# StarFive VisionFive 2 v1.3b register map
File version: 0.1
Registers are 32-bit, read-write, no defined reset value unless marked. A register's access mark holds for its fields unless they carry their own. Offsets are from the block's base; [hi:lo] are bit positions; {n}, {i} and the like mark numbered series; 'fields as' and 'values as' point back to an identical list.

## sifive_clint0_0 — From sifive,clint0, peripheral generator
Base 0x02000000
{0x0+4i} msip_{i} (i=0..4) — MSIP Register for hart {i}
{0x4000+8i} mtimecmp_{i} 64-bit (i=0..4) — MTIMECMP Register for hart {i}
0xBFF8 mtime 64-bit

## sifive_plic0_0 — From sifive,plic0, peripheral generator
Base 0x0C000000
{0x0+4i} priority_{i} (i=1..136) — PRIORITY Register for interrupt id {i}
{0x1000+4i} pending_{i} (i=0..3) — PENDING Register for interrupt ids {32i+31} to {32i}
0x1010 pending_4 — PENDING Register for interrupt ids 136 to 128
{0x2000+0x80*i} enable_0_{i} (i=0..4) — ENABLE Register for interrupt ids 31 to 0 for hart {i}
{0x2004+0x80*i} enable_1_{i} (i=0..4) — ENABLE Register for interrupt ids 63 to 32 for hart {i}
{0x2008+0x80*i} enable_2_{i} (i=0..4) — ENABLE Register for interrupt ids 95 to 64 for hart {i}
{0x200C+0x80*i} enable_3_{i} (i=0..4) — ENABLE Register for interrupt ids 127 to 96 for hart {i}
{0x2010+0x80*i} enable_4_{i} (i=0..4) — ENABLE Register for interrupt ids 136 to 128 for hart {i}
{0x200000+0x1000*i} threshold_{i} (i=0..4) — PRIORITY THRESHOLD Register for hart {i}
{0x200004+0x1000*i} claimplete_{i} (i=0..4) — CLAIM and COMPLETE Register for hart {i}

## starfive_jh7110_pwm_0 — From starfive,jh7110-pwm, peripheral generator
Base 0x120D0000
0x00 cntr — PTC counter register
  [31:0] cntr — PWM PTC counter
0x04 hrc — PTC duty-cycle register
  [31:0] hrc — PWM PTC duty-cycle value
0x08 lrc — PTC period register
  [31:0] lrc — PWM PTC period value
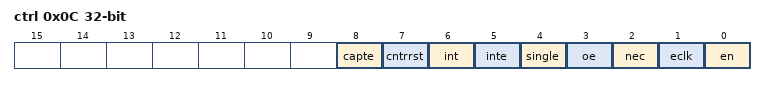
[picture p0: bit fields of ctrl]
0x0C ctrl — PTC control register
  [8] capte — PWM PTC capte
  [7] cntrrst — PWM PTC counter reset
  [6] int — PWM PTC interrupt
  [5] inte — PWM PTC interrupt enable
  [4] single — PWM PTC single
  [3] oe — PWM PTC oe
  [2] nec — PWM PTC nec
  [1] eclk — PWM PTC enable clock
  [0] en — PWM PTC enable

## starfive_jh7110_aoncrg_0 — From starfive,jh7110-aoncrg, peripheral generator
Base 0x17000000
0x00 clk_osc — Oscillator Clock
  [23:0] clk_divcfg — Clock divider coefficient: Max=4, Default=4, Min=4, Typical=4
0x04 clk_aon_apb — AON APB Function Clock
  [29:24] clk_mux_sel — Clock multiplexing selector: clk_osc_div4, clk_osc
0x08 clk_ahb_gmac5 — AHB GMAC5 Clock
  [31] clk_icg — 1: Clock enable, 0: Clock disable
0x0C clk_axi_gmac5 — AXI GMAC5 Clock
  [31] clk_icg — 1: Clock enable, 0: Clock disable
0x10 clk_gmac0_rmii_rtx — GMAC0 RMII RTX Clock
  [23:0] clk_divcfg — Clock divider coefficient: Max=30, Default=2, Min=2, Typical=2
0x14 clk_gmac5_axi64_tx — GMAC5 AXI64 Clock Transmitter
  [29:24] clk_mux_sel — Clock multiplexing selector: u0_sys_crg_clk_gmac0_gtxclk, clk_gmac0_rmii_rtx
0x18 clk_gmac5_axi64_txi — GMAC5 AXI64 Clock Transmission Inverter
  [30] clk_polarity — 1: Clock inverter, 0: Clock buffer
0x1C clk_gmac5_axi64_rx — GMAC5 AXI64 Clock Receiver
  [23:0] dly_chain_sel — Selector delay chain stage number, totally 32 stages, -50 ps each stage. The register value indicates the delay chain stage number. For example, diy_chain_sel=1 means to delay 1 stage.
0x20 clk_gmac5_axi64_rxi — GMAC5 AXI64 Clock Receiving Inverter
  [30] clk_polarity — 1: Clock inverter, 0: Clock buffer
0x24 clk_optc_apb — OPTC APB Clock
  [31] clk_icg — 1: Clock enable, 0: Clock disable
0x28 clk_rtc_hms_apb — RTC HMS APB Clock
  [31] clk_icg — 1: Clock enable, 0: Clock disable
0x2C clk_rtc_internal — RTC Internal Clock
  [23:0] clk_divcfg — Clock divider coefficient: Max=1022, Default=750, Min=750, Typical=750
0x30 clk_rtc_hms_osc32k — RTC HMS Clock Oscillator 32K
  [29:24] clk_mux_sel — Clock multiplexing selector: clk_rtc, clk_rtc_internal
0x34 clk_rtc_hms_cal — RTC HMS Clock Calculator
  [31] clk_icg — 1: Clock enable, 0: Clock disable
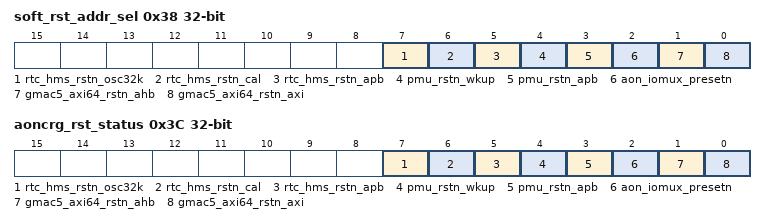
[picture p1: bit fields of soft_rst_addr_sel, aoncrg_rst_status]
0x38 soft_rst_addr_sel — Software RESET Address Selector
  [7] rtc_hms_rstn_osc32k — 1: Assert reset, 0: De-assert reset
  [6] rtc_hms_rstn_cal — 1: Assert reset, 0: De-assert reset
  [5] rtc_hms_rstn_apb — 1: Assert reset, 0: De-assert reset
  [4] pmu_rstn_wkup — 1: Assert reset, 0: De-assert reset
  [3] pmu_rstn_apb — 1: Assert reset, 0: De-assert reset
  [2] aon_iomux_presetn — 1: Assert reset, 0: De-assert reset
  [1] gmac5_axi64_rstn_ahb — 1: Assert reset, 0: De-assert reset
  [0] gmac5_axi64_rstn_axi — 1: Assert reset, 0: De-assert reset
0x3C aoncrg_rst_status — AONCRG RESET Status
  fields as soft_rst_addr_sel

## starfive_jh7110_aon_syscon_0 — From starfive,jh7110-aon-syscon, peripheral generator
Base 0x17010000
0x00 aon_sysconsaif_syscfg0
  [31:0] aon_gp_reg
0x04 aon_sysconsaif_syscfg4
  [3:0] u0_boot_ctrl_boot_status ro
0x08 aon_sysconsaif_syscfg8
  [31:0] u0_boot_ctrl_boot_vector_31_0 ro
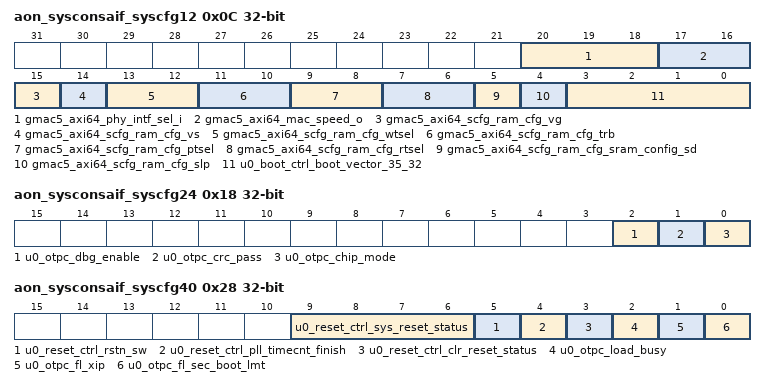
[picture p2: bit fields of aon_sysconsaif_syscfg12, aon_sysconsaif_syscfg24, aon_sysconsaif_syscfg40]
0x0C aon_sysconsaif_syscfg12
  [20:18] gmac5_axi64_phy_intf_sel_i — Active PHY Selected. When you have multiple GMAC PHY interfaces in your configuration, this field indicates the sampled value of the PHY selector during reset de-assertion. Values: 0x0 - GMII or MII, 0x1 - RGMII, 0x2 - SGMII, 0x3 - TBI, 0x4 - RMII, 0x5 - RTBI, 0x6 - SMII, 0x7 - REVMII
  [17:16] gmac5_axi64_mac_speed_o ro
  [15] gmac5_axi64_scfg_ram_cfg_vg — SRAM/ROM configuration. VG: timing setting for debug purpose, default is 1'b1.
  [14] gmac5_axi64_scfg_ram_cfg_vs — SRAM/ROM configuration. VS: timing setting for debug purpose, default is 1'b1.
  [13:12] gmac5_axi64_scfg_ram_cfg_wtsel — SRAM/ROM configuration. WTSEL: timing setting for debug purpose, default is 2'b01.
  [11:10] gmac5_axi64_scfg_ram_cfg_trb — SRAM/ROM configuration. TRB: timing setting for debug purpose, default is 2'b01.
  [9:8] gmac5_axi64_scfg_ram_cfg_ptsel — SRAM/ROM configuration. PTSEL: timing setting for debug purpose, default is 2'b01.
  [7:6] gmac5_axi64_scfg_ram_cfg_rtsel — SRAM/ROM configuration. RTSEL: timing setting for debug purpose, default is 2'b01.
  [5] gmac5_axi64_scfg_ram_cfg_sram_config_sd — SRAM/ROM configuration. SD: shutdown enable, high active, default is low.
  [4] gmac5_axi64_scfg_ram_cfg_slp — SRAM/ROM configuration. SLP: sleep enable, high active, default is low.
  [3:0] u0_boot_ctrl_boot_vector_35_32 ro
0x10 aon_sysconsaif_syscfg16
  [31:0] gmac5_axi64_ptp_timestamp_o_31_0 ro
0x14 aon_sysconsaif_syscfg20
  [31:0] gmac5_axi64_ptp_timestamp_o_63_32 ro
0x18 aon_sysconsaif_syscfg24
  [2] u0_otpc_dbg_enable ro, [1] u0_otpc_crc_pass ro, [0] u0_otpc_chip_mode ro
0x1C aon_sysconsaif_syscfg28
  [31:0] u0_otpc_fl_func_lock ro
0x20 aon_sysconsaif_syscfg32
  [31:0] u0_otpc_fl_pll0_lock ro
0x24 aon_sysconsaif_syscfg36
  [31:0] u0_otpc_fl_pll1_lock ro
0x28 aon_sysconsaif_syscfg40
  [9:6] u0_reset_ctrl_sys_reset_status ro, [5] u0_reset_ctrl_rstn_sw, [4] u0_reset_ctrl_pll_timecnt_finish ro, [3] u0_reset_ctrl_clr_reset_status, [2] u0_otpc_load_busy ro, [1] u0_otpc_fl_xip ro, [0] u0_otpc_fl_sec_boot_lmt ro
